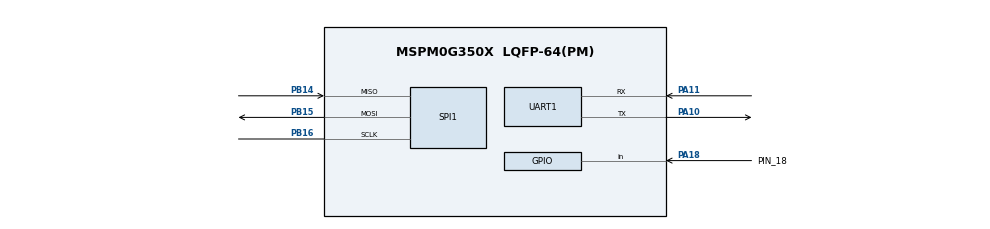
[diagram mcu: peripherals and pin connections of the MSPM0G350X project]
/**
 * @cliArgs --device "MSPM0G350X" --package "LQFP-64(PM)" --part "Default" --product "mspm0_sdk@1.30.00.03"
 * @versions {"tool":"1.19.0+3426"}
 */

/**
 * Import the modules used in this configuration.
 */
const GPIO    = scripting.addModule("/ti/driverlib/GPIO", {}, false);
const GPIO1   = GPIO.addInstance();
const GPIO2   = GPIO.addInstance();
const GPIO3   = GPIO.addInstance();
const SPI     = scripting.addModule("/ti/driverlib/SPI", {}, false);
const SPI1    = SPI.addInstance();
const SYSCTL  = scripting.addModule("/ti/driverlib/SYSCTL");
const SYSTICK = scripting.addModule("/ti/driverlib/SYSTICK");
const UART    = scripting.addModule("/ti/driverlib/UART", {}, false);
const UART1   = UART.addInstance();

/**
 * Write custom configuration values to the imported modules.
 */
const gate7  = system.clockTree["MFCLKGATE"];
gate7.enable = true;

GPIO1.$name                              = "LED1";
GPIO1.port                               = "PORTA";
GPIO1.associatedPins[0].$name            = "PIN_14";
GPIO1.associatedPins[0].internalResistor = "PULL_DOWN";
GPIO1.associatedPins[0].assignedPin      = "14";

const Board = scripting.addModule("/ti/driverlib/Board", {}, false);

GPIO2.$name                              = "KEY";
GPIO2.port                               = "PORTA";
GPIO2.associatedPins[0].$name            = "PIN_18";
GPIO2.associatedPins[0].direction        = "INPUT";
GPIO2.associatedPins[0].assignedPin      = "18";
GPIO2.associatedPins[0].internalResistor = "PULL_DOWN";
GPIO2.associatedPins[0].interruptEn      = true;
GPIO2.associatedPins[0].polarity         = "RISE";
GPIO2.associatedPins[0].pin.$assign      = "PA18";

GPIO3.$name                          = "CS";
GPIO3.associatedPins[0].$name        = "PIN";
GPIO3.associatedPins[0].assignedPort = "PORTB";
GPIO3.associatedPins[0].assignedPin  = "17";

SPI1.$name                              = "SPI";
SPI1.targetBitRate                      = 16000000;
SPI1.chipSelect                         = ["1"];
SPI1.peripheral.$assign                 = "SPI1";
SPI1.peripheral.sclkPin.$assign         = "PB16";
SPI1.peripheral.mosiPin.$assign         = "PB15";
SPI1.peripheral.misoPin.$assign         = "PB14";
SPI1.sclkPinConfig.$name                = "ti_driverlib_gpio_GPIOPinGeneric2";
SPI1.sclkPinConfig.direction            = scripting.forceWrite("OUTPUT");
SPI1.sclkPinConfig.onlyInternalResistor = scripting.forceWrite(false);
SPI1.sclkPinConfig.passedPeripheralType = scripting.forceWrite("Digital");
SPI1.mosiPinConfig.$name                = "ti_driverlib_gpio_GPIOPinGeneric3";
SPI1.mosiPinConfig.direction            = scripting.forceWrite("OUTPUT");
SPI1.mosiPinConfig.hideOutputInversion  = scripting.forceWrite(false);
SPI1.mosiPinConfig.onlyInternalResistor = scripting.forceWrite(false);
SPI1.mosiPinConfig.passedPeripheralType = scripting.forceWrite("Digital");
SPI1.misoPinConfig.$name                = "ti_driverlib_gpio_GPIOPinGeneric4";
SPI1.misoPinConfig.onlyInternalResistor = scripting.forceWrite(false);
SPI1.misoPinConfig.passedPeripheralType = scripting.forceWrite("Digital");
SPI1.cs1PinConfig.$name                 = "ti_driverlib_gpio_GPIOPinGeneric6";

SYSCTL.forceDefaultClkConfig = true;
SYSCTL.clockTreeEn           = true;

SYSTICK.periodEnable      = true;
SYSTICK.systickEnable     = true;
SYSTICK.interruptPriority = "0";
SYSTICK.period            = 32;

UART1.$name                    = "UART_0";
UART1.uartClkSrc               = "MFCLK";
UART1.enabledInterrupts        = ["RX"];
UART1.peripheral.$assign       = "UART0";
UART1.peripheral.rxPin.$assign = "PA11";
UART1.peripheral.txPin.$assign = "PA10";
UART1.txPinConfig.$name        = "ti_driverlib_gpio_GPIOPinGeneric0";
UART1.rxPinConfig.$name        = "ti_driverlib_gpio_GPIOPinGeneric1";

/**
 * Pinmux solution for unlocked pins/peripherals. This ensures that minor changes to the automatic solver in a future
 * version of the tool will not impact the pinmux you originally saw.  These lines can be completely deleted in order to
 * re-solve from scratch.
 */
GPIO1.associatedPins[0].pin.$suggestSolution = "PA14";
Board.peripheral.$suggestSolution            = "DEBUGSS";
Board.peripheral.swclkPin.$suggestSolution   = "PA20";
Board.peripheral.swdioPin.$suggestSolution   = "PA19";
GPIO3.associatedPins[0].pin.$suggestSolution = "PB17";
SPI1.peripheral.cs1Pin.$suggestSolution      = "PA27";
